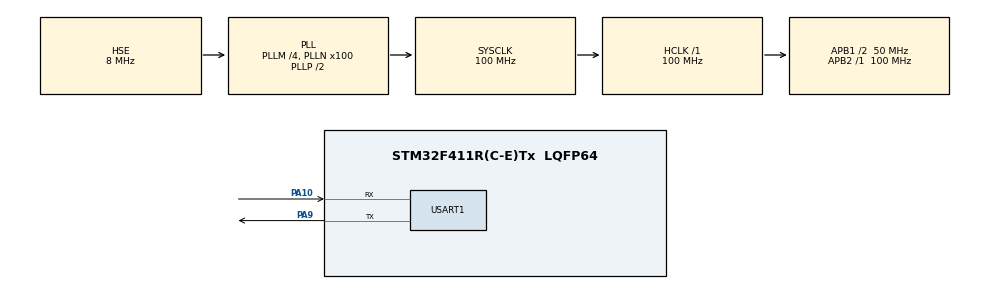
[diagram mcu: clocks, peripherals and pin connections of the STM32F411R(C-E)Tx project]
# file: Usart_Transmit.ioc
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Mcu.Family=STM32F4
RCC.PLLSourceVirtual=RCC_PLLSOURCE_HSE
RCC.CortexFreq_Value=100000000
PA10.Mode=Asynchronous
PH1\ -\ OSC_OUT.Mode=HSE-External-Oscillator
RCC.APB1CLKDivider=RCC_HCLK_DIV2
RCC.SYSCLKSource=RCC_SYSCLKSOURCE_PLLCLK
ProjectManager.StackSize=0x400
PA13.Signal=SYS_JTMS-SWDIO
PA9.Mode=Asynchronous
PH0\ -\ OSC_IN.Mode=HSE-External-Oscillator
PH0\ -\ OSC_IN.Signal=RCC_OSC_IN
ProjectManager.TargetToolchain=MDK-ARM V5.27
RCC.HCLKFreq_Value=100000000
RCC.APB2TimFreq_Value=100000000
PA9.Signal=USART1_TX
RCC.LSE_VALUE=32768
RCC.AHBFreq_Value=100000000
RCC.HSE_VALUE=8000000
PH1\ -\ OSC_OUT.Signal=RCC_OSC_OUT
board=NUCLEO-F411RE
RCC.VCOOutputFreq_Value=200000000
RCC.APB2Freq_Value=100000000
PA14.Mode=Serial_Wire
PA13.Mode=Serial_Wire
Mcu.Name=STM32F411R(C-E)Tx
RCC.FLatency-AdvancedSettings=FLASH_LATENCY_3
RCC.48MHZClocksFreq_Value=50000000
RCC.SYSCLKFreq_VALUE=100000000
Mcu.Package=LQFP64
USART1.VirtualMode=VM_ASYNC
PA10.Signal=USART1_RX
PA14.Signal=SYS_JTCK-SWCLK
ProjectManager.HeapSize=0x200
RCC.HSI_VALUE=16000000
NVIC.PriorityGroup=NVIC_PRIORITYGROUP_0
RCC.PLLM=4
RCC.PLLN=100
RCC.APB1TimFreq_Value=100000000
RCC.APB1Freq_Value=50000000

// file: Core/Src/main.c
/* USER CODE BEGIN Header */
/**
  ******************************************************************************
  * @file           : main.c
  * @brief          : Main program body
  ******************************************************************************
  * @attention
  *
  * <h2><center>&copy; Copyright (c) 2020 STMicroelectronics.
  * All rights reserved.</center></h2>
  *
  * This software component is licensed by ST under BSD 3-Clause license,
  * the "License"; You may not use this file except in compliance with the
  * License. You may obtain a copy of the License at:
  *                        opensource.org/licenses/BSD-3-Clause
  *
  ******************************************************************************
  */
/* USER CODE END Header */
#include "main.h"

/* USER CODE BEGIN Includes */
#include "string.h"
#include "stdio.h"

/* USER CODE END Includes */

UART_HandleTypeDef huart1;

void SystemClock_Config(void);
static void MX_GPIO_Init(void);
static void MX_USART1_UART_Init(void);
/* USER CODE BEGIN PFP */
uint8_t number=0;
char data[32];
//static char* data=" "; //It is not correct
static char* name="passing second :\t\r";
//char name[32]= " " ;

/* USER CODE END PFP */

int main(void)
{

  /* MCU Configuration--------------------------------------------------------*/

  /* Reset of all peripherals, Initializes the Flash interface and the Systick. */
  HAL_Init();

  /* Configure the system clock */
  SystemClock_Config();

  /* Initialize all configured peripherals */
  MX_GPIO_Init();
  MX_USART1_UART_Init();
  /* USER CODE BEGIN 2 */

	//HAL_UART_Transmit(&huart1,(uint8_t*)name,strlen(name),1000);
	//HAL_UART_Transmit(&huart1,(uint8_t *)name, sprintf(name, "passing second\t\r"), 1000);
	//HAL_Delay(1000);

  /* USER CODE END 2 */

  /* Infinite loop */
  while (1)
  {

    /* USER CODE BEGIN 3 */
		number++;
		if(number>59)
			number=0;

		HAL_UART_Transmit(&huart1,(uint8_t*)name,strlen(name),1000);
	  HAL_UART_Transmit(&huart1,(uint8_t*)data,sprintf(data," %d \n\r",number),1000);// May be we can use if(hal_ok)
		HAL_Delay(1000);

  }
  /* USER CODE END 3 */
}

void SystemClock_Config(void)
{
  RCC_OscInitTypeDef RCC_OscInitStruct = {0};
  RCC_ClkInitTypeDef RCC_ClkInitStruct = {0};

  /** Configure the main internal regulator output voltage
  */
  __HAL_RCC_PWR_CLK_ENABLE();
  __HAL_PWR_VOLTAGESCALING_CONFIG(PWR_REGULATOR_VOLTAGE_SCALE1);
  /** Initializes the RCC Oscillators according to the specified parameters
  * in the RCC_OscInitTypeDef structure.
  */
  RCC_OscInitStruct.OscillatorType = RCC_OSCILLATORTYPE_HSE;
  RCC_OscInitStruct.HSEState = RCC_HSE_ON;
  RCC_OscInitStruct.PLL.PLLState = RCC_PLL_ON;
  RCC_OscInitStruct.PLL.PLLSource = RCC_PLLSOURCE_HSE;
  RCC_OscInitStruct.PLL.PLLM = 4;
  RCC_OscInitStruct.PLL.PLLN = 100;
  RCC_OscInitStruct.PLL.PLLP = RCC_PLLP_DIV2;
  RCC_OscInitStruct.PLL.PLLQ = 4;
  if (HAL_RCC_OscConfig(&RCC_OscInitStruct) != HAL_OK)
  {
    Error_Handler();
  }
  /** Initializes the CPU, AHB and APB buses clocks
  */
  RCC_ClkInitStruct.ClockType = RCC_CLOCKTYPE_HCLK|RCC_CLOCKTYPE_SYSCLK
                              |RCC_CLOCKTYPE_PCLK1|RCC_CLOCKTYPE_PCLK2;
  RCC_ClkInitStruct.SYSCLKSource = RCC_SYSCLKSOURCE_PLLCLK;
  RCC_ClkInitStruct.AHBCLKDivider = RCC_SYSCLK_DIV1;
  RCC_ClkInitStruct.APB1CLKDivider = RCC_HCLK_DIV2;
  RCC_ClkInitStruct.APB2CLKDivider = RCC_HCLK_DIV1;

  if (HAL_RCC_ClockConfig(&RCC_ClkInitStruct, FLASH_LATENCY_3) != HAL_OK)
  {
    Error_Handler();
  }
}

static void MX_USART1_UART_Init(void)
{

  huart1.Instance = USART1;
  huart1.Init.BaudRate = 115200;
  huart1.Init.WordLength = UART_WORDLENGTH_8B;
  huart1.Init.StopBits = UART_STOPBITS_1;
  huart1.Init.Parity = UART_PARITY_NONE;
  huart1.Init.Mode = UART_MODE_TX_RX;
  huart1.Init.HwFlowCtl = UART_HWCONTROL_NONE;
  huart1.Init.OverSampling = UART_OVERSAMPLING_16;
  if (HAL_UART_Init(&huart1) != HAL_OK)
  {
    Error_Handler();
  }

}

static void MX_GPIO_Init(void)
{

  /* GPIO Ports Clock Enable */
  __HAL_RCC_GPIOH_CLK_ENABLE();
  __HAL_RCC_GPIOA_CLK_ENABLE();

}

void Error_Handler(void)
{
}

/************************ (C) COPYRIGHT STMicroelectronics *****END OF FILE****/
